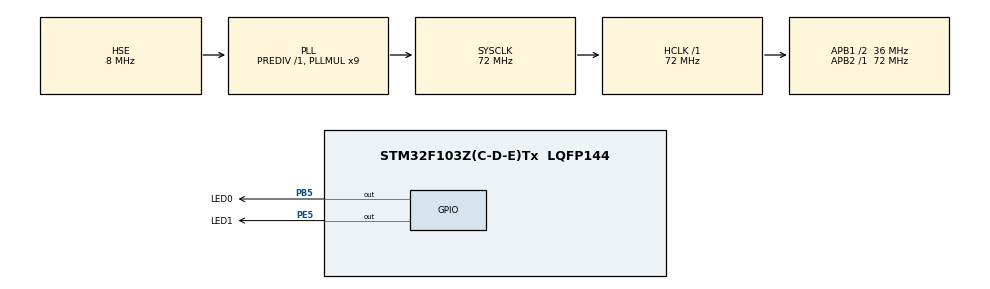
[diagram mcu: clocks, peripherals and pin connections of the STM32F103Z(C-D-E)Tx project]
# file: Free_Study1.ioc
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FREERTOS.Tasks01=Task_LED0,0,128,Func_LED0,Default,NULL,Dynamic,NULL,NULL;Task_LED1,0,128,Func_LED1,Default,NULL,Dynamic,NULL,NULL
Mcu.Family=STM32F1
Mcu.Name=STM32F103Z(C-D-E)Tx
Mcu.Package=LQFP144
NVIC.PriorityGroup=NVIC_PRIORITYGROUP_4
NVIC.TIM4_IRQn=true\:0\:0\:false\:false\:true\:false\:false\:true
NVIC.TimeBase=TIM4_IRQn
NVIC.TimeBaseIP=TIM4
OSC_IN.Mode=HSE-External-Oscillator
OSC_IN.Signal=RCC_OSC_IN
OSC_OUT.Mode=HSE-External-Oscillator
OSC_OUT.Signal=RCC_OSC_OUT
PA13.Mode=Serial_Wire
PA13.Signal=SYS_JTMS-SWDIO
PA14.Mode=Serial_Wire
PA14.Signal=SYS_JTCK-SWCLK
PB5.GPIO_Label=LED0
PB5.Signal=GPIO_Output
PE5.GPIO_Label=LED1
PE5.Signal=GPIO_Output
ProjectManager.HeapSize=0x200
ProjectManager.StackSize=0x400
ProjectManager.TargetToolchain=STM32CubeIDE
RCC.AHBFreq_Value=72000000
RCC.APB1CLKDivider=RCC_HCLK_DIV2
RCC.APB1Freq_Value=36000000
RCC.APB1TimFreq_Value=72000000
RCC.APB2Freq_Value=72000000
RCC.APB2TimFreq_Value=72000000
RCC.HCLKFreq_Value=72000000
RCC.PLLMUL=RCC_PLL_MUL9
RCC.PLLSourceVirtual=RCC_PLLSOURCE_HSE
RCC.SYSCLKFreq_VALUE=72000000
RCC.SYSCLKSource=RCC_SYSCLKSOURCE_PLLCLK
RCC.USBFreq_Value=72000000
VP_FREERTOS_VS_CMSIS_V1.Mode=CMSIS_V1
VP_SYS_VS_tim4.Mode=TIM4
board=custom

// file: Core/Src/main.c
/* USER CODE BEGIN Header */
/**
  ******************************************************************************
  * @file           : main.c
  * @brief          : Main program body
  ******************************************************************************
  * @attention
  *
  * <h2><center>&copy; Copyright (c) 2020 STMicroelectronics.
  * All rights reserved.</center></h2>
  *
  * This software component is licensed by ST under BSD 3-Clause license,
  * the "License"; You may not use this file except in compliance with the
  * License. You may obtain a copy of the License at:
  *                        opensource.org/licenses/BSD-3-Clause
  *
  ******************************************************************************
  */
/* USER CODE END Header */

#include "main.h"
#include "cmsis_os.h"

osThreadId Task_LED0Handle;
osThreadId Task_LED1Handle;

void SystemClock_Config(void);
static void MX_GPIO_Init(void);
void Func_LED0(void const * argument);
void Func_LED1(void const * argument);

int main(void)
{

  /* MCU Configuration--------------------------------------------------------*/

  /* Reset of all peripherals, Initializes the Flash interface and the Systick. */
  HAL_Init();

  /* Configure the system clock */
  SystemClock_Config();

  /* Initialize all configured peripherals */
  MX_GPIO_Init();

  /* Create the thread(s) */
  /* definition and creation of Task_LED0 */
  osThreadDef(Task_LED0, Func_LED0, osPriorityNormal, 0, 128);
  Task_LED0Handle = osThreadCreate(osThread(Task_LED0), NULL);

  /* definition and creation of Task_LED1 */
  osThreadDef(Task_LED1, Func_LED1, osPriorityNormal, 0, 128);
  Task_LED1Handle = osThreadCreate(osThread(Task_LED1), NULL);

  /* Start scheduler */
  osKernelStart();

  /* We should never get here as control is now taken by the scheduler */

  /* Infinite loop */
  while (1)
  {

  }
}

void SystemClock_Config(void)
{
  RCC_OscInitTypeDef RCC_OscInitStruct = {0};
  RCC_ClkInitTypeDef RCC_ClkInitStruct = {0};

  /** Initializes the CPU, AHB and APB busses clocks
  */
  RCC_OscInitStruct.OscillatorType = RCC_OSCILLATORTYPE_HSE;
  RCC_OscInitStruct.HSEState = RCC_HSE_ON;
  RCC_OscInitStruct.HSEPredivValue = RCC_HSE_PREDIV_DIV1;
  RCC_OscInitStruct.HSIState = RCC_HSI_ON;
  RCC_OscInitStruct.PLL.PLLState = RCC_PLL_ON;
  RCC_OscInitStruct.PLL.PLLSource = RCC_PLLSOURCE_HSE;
  RCC_OscInitStruct.PLL.PLLMUL = RCC_PLL_MUL9;
  if (HAL_RCC_OscConfig(&RCC_OscInitStruct) != HAL_OK)
  {
    Error_Handler();
  }
  /** Initializes the CPU, AHB and APB busses clocks
  */
  RCC_ClkInitStruct.ClockType = RCC_CLOCKTYPE_HCLK|RCC_CLOCKTYPE_SYSCLK
                              |RCC_CLOCKTYPE_PCLK1|RCC_CLOCKTYPE_PCLK2;
  RCC_ClkInitStruct.SYSCLKSource = RCC_SYSCLKSOURCE_PLLCLK;
  RCC_ClkInitStruct.AHBCLKDivider = RCC_SYSCLK_DIV1;
  RCC_ClkInitStruct.APB1CLKDivider = RCC_HCLK_DIV2;
  RCC_ClkInitStruct.APB2CLKDivider = RCC_HCLK_DIV1;

  if (HAL_RCC_ClockConfig(&RCC_ClkInitStruct, FLASH_LATENCY_2) != HAL_OK)
  {
    Error_Handler();
  }
}

static void MX_GPIO_Init(void)
{
  GPIO_InitTypeDef GPIO_InitStruct = {0};

  /* GPIO Ports Clock Enable */
  __HAL_RCC_GPIOE_CLK_ENABLE();
  __HAL_RCC_GPIOA_CLK_ENABLE();
  __HAL_RCC_GPIOB_CLK_ENABLE();

  /*Configure GPIO pin Output Level */
  HAL_GPIO_WritePin(LED1_GPIO_Port, LED1_Pin, GPIO_PIN_RESET);

  /*Configure GPIO pin Output Level */
  HAL_GPIO_WritePin(LED0_GPIO_Port, LED0_Pin, GPIO_PIN_RESET);

  /*Configure GPIO pin : LED1_Pin */
  GPIO_InitStruct.Pin = LED1_Pin;
  GPIO_InitStruct.Mode = GPIO_MODE_OUTPUT_PP;
  GPIO_InitStruct.Pull = GPIO_NOPULL;
  GPIO_InitStruct.Speed = GPIO_SPEED_FREQ_LOW;
  HAL_GPIO_Init(LED1_GPIO_Port, &GPIO_InitStruct);

  /*Configure GPIO pin : LED0_Pin */
  GPIO_InitStruct.Pin = LED0_Pin;
  GPIO_InitStruct.Mode = GPIO_MODE_OUTPUT_PP;
  GPIO_InitStruct.Pull = GPIO_NOPULL;
  GPIO_InitStruct.Speed = GPIO_SPEED_FREQ_LOW;
  HAL_GPIO_Init(LED0_GPIO_Port, &GPIO_InitStruct);

}

void Func_LED0(void const * argument)
{
  /* USER CODE BEGIN 5 */
  /* Infinite loop */
  for(;;)
  {
    osDelay(1000);
    HAL_GPIO_WritePin(LED0_GPIO_Port,LED0_Pin,GPIO_PIN_RESET);
    osDelay(500);
    HAL_GPIO_WritePin(LED0_GPIO_Port,LED0_Pin,GPIO_PIN_SET);
  }
  /* USER CODE END 5 */
}

void Func_LED1(void const * argument)
{
  /* USER CODE BEGIN Func_LED1 */
  /* Infinite loop */
  for(;;)
  {
	  HAL_GPIO_TogglePin(LED1_GPIO_Port, LED1_Pin);
	  osDelay(500);
  }
  /* USER CODE END Func_LED1 */
}

void HAL_TIM_PeriodElapsedCallback(TIM_HandleTypeDef *htim)
{
  if (htim->Instance == TIM4) {
    HAL_IncTick();
  }
}

void Error_Handler(void)
{
}

/************************ (C) COPYRIGHT STMicroelectronics *****END OF FILE****/
